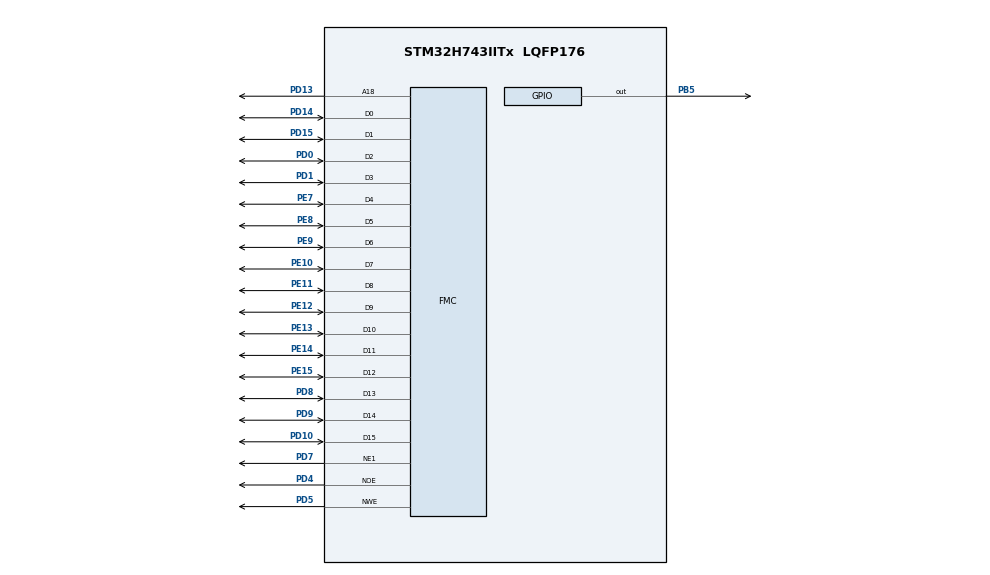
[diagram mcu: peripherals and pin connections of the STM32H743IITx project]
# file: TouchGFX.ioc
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CORTEX_M7.AccessPermission_S-Cortex_Memory_Protection_Unit_Region1_Settings_S=MPU_REGION_FULL_ACCESS
CORTEX_M7.BaseAddress_S-Cortex_Memory_Protection_Unit_Region1_Settings_S=0x60000000
CORTEX_M7.DisableExec_S-Cortex_Memory_Protection_Unit_Region1_Settings_S=MPU_INSTRUCTION_ACCESS_DISABLE
CORTEX_M7.Enable_S-Cortex_Memory_Protection_Unit_Region1_Settings_S=MPU_REGION_ENABLE
CORTEX_M7.Enable_Spec=__NULL
CORTEX_M7.Size_S-Cortex_Memory_Protection_Unit_Region1_Settings_S=MPU_REGION_SIZE_256MB
CORTEX_M7.default_mode_Activation=1
FMC.AddressSetupTime1=3
FMC.BusTurnAroundDuration1=0
FMC.DataSetupTime1=36
FMC.ExtendedAddressSetupTime1=0
FMC.ExtendedBusTurnAroundDuration1=0
FMC.ExtendedDataSetupTime1=4
FMC.ExtendedMode1=FMC_EXTENDED_MODE_ENABLE
Mcu.Family=STM32H7
Mcu.Name=STM32H743IITx
Mcu.Package=LQFP176
NVIC.PriorityGroup=NVIC_PRIORITYGROUP_4
PA13\ (JTMS/SWDIO).Mode=Serial_Wire
PA13\ (JTMS/SWDIO).Signal=DEBUG_JTMS-SWDIO
PA14\ (JTCK/SWCLK).Mode=Serial_Wire
PA14\ (JTCK/SWCLK).Signal=DEBUG_JTCK-SWCLK
PB5.GPIO_ModeDefaultOutputPP=GPIO_MODE_OUTPUT_PP
PB5.GPIO_PuPd=GPIO_PULLUP
PB5.PinState=GPIO_PIN_SET
PB5.Signal=GPIO_Output
PC14-OSC32_IN\ (OSC32_IN).Mode=LSE-External-Oscillator
PC14-OSC32_IN\ (OSC32_IN).Signal=RCC_OSC32_IN
PC15-OSC32_OUT\ (OSC32_OUT).Mode=LSE-External-Oscillator
PC15-OSC32_OUT\ (OSC32_OUT).Signal=RCC_OSC32_OUT
PD0.Signal=FMC_D2_DA2
PD1.Signal=FMC_D3_DA3
PD10.Signal=FMC_D15_DA15
PD13.Signal=FMC_A18
PD14.Signal=FMC_D0_DA0
PD15.Signal=FMC_D1_DA1
PD4.Signal=FMC_NOE
PD5.Signal=FMC_NWE
PD7.Mode=NorPsramChipSelect1_1
PD7.Signal=FMC_NE1
PD8.Signal=FMC_D13_DA13
PD9.Signal=FMC_D14_DA14
PE10.Signal=FMC_D7_DA7
PE11.Signal=FMC_D8_DA8
PE12.Signal=FMC_D9_DA9
PE13.Signal=FMC_D10_DA10
PE14.Signal=FMC_D11_DA11
PE15.Signal=FMC_D12_DA12
PE7.Signal=FMC_D4_DA4
PE8.Signal=FMC_D5_DA5
PE9.Signal=FMC_D6_DA6
PH0-OSC_IN\ (PH0).Mode=HSE-External-Oscillator
PH0-OSC_IN\ (PH0).Signal=RCC_OSC_IN
PH1-OSC_OUT\ (PH1).Mode=HSE-External-Oscillator
PH1-OSC_OUT\ (PH1).Signal=RCC_OSC_OUT
ProjectManager.HeapSize=0x200
ProjectManager.StackSize=0x400
ProjectManager.TargetToolchain=STM32CubeIDE
RCC.ADCFreq_Value=50390625
RCC.APB1Freq_Value=120000000
RCC.APB2Freq_Value=120000000
RCC.APB3Freq_Value=120000000
RCC.APB4Freq_Value=120000000
RCC.CortexFreq_Value=480000000
RCC.D1PPRE=RCC_APB3_DIV2
RCC.D2PPRE1=RCC_APB1_DIV2
RCC.D2PPRE2=RCC_APB2_DIV2
RCC.D3PPRE=RCC_APB4_DIV2
RCC.DIVM1=5
RCC.DIVN1=192
RCC.HCLKFreq_Value=240000000
RCC.HPRE=RCC_HCLK_DIV2
RCC.PLLSourceVirtual=RCC_PLLSOURCE_HSE
RCC.SYSCLKFreq_VALUE=480000000
RCC.SYSCLKSource=RCC_SYSCLKSOURCE_PLLCLK
RCC.USBFreq_Value=480000000
SH.FMC_A18.0=FMC_A18,A18_1
SH.FMC_D0_DA0.0=FMC_D0,16b-d1
SH.FMC_D10_DA10.0=FMC_D10,16b-d1
SH.FMC_D11_DA11.0=FMC_D11,16b-d1
SH.FMC_D12_DA12.0=FMC_D12,16b-d1
SH.FMC_D13_DA13.0=FMC_D13,16b-d1
SH.FMC_D14_DA14.0=FMC_D14,16b-d1
SH.FMC_D15_DA15.0=FMC_D15,16b-d1
SH.FMC_D1_DA1.0=FMC_D1,16b-d1
SH.FMC_D2_DA2.0=FMC_D2,16b-d1
SH.FMC_D3_DA3.0=FMC_D3,16b-d1
SH.FMC_D4_DA4.0=FMC_D4,16b-d1
SH.FMC_D5_DA5.0=FMC_D5,16b-d1
SH.FMC_D6_DA6.0=FMC_D6,16b-d1
SH.FMC_D7_DA7.0=FMC_D7,16b-d1
SH.FMC_D8_DA8.0=FMC_D8,16b-d1
SH.FMC_D9_DA9.0=FMC_D9,16b-d1
SH.FMC_NOE.0=FMC_NOE,Lcd1
SH.FMC_NWE.0=FMC_NWE,Lcd1
STMicroelectronics.X-CUBE-TOUCHGFX.4.24.2.ApplicationCcGraphicsJjApplication=TouchGFXOoGenerator
STMicroelectronics.X-CUBE-TOUCHGFX.4.24.2.tgfx_buffering_strategy=Partial
STMicroelectronics.X-CUBE-TOUCHGFX.4.24.2.tgfx_custom_height=800
STMicroelectronics.X-CUBE-TOUCHGFX.4.24.2.tgfx_custom_width=480
STMicroelectronics.X-CUBE-TOUCHGFX.4.24.2_IsPackSelfContextualization=true
VP_CRC_VS_CRC.Mode=CRC_Activate
VP_MEMORYMAP_VS_MEMORYMAP.Mode=CurAppReg
VP_STMicroelectronics.X-CUBE-TOUCHGFX_VS_GraphicsJjApplication_4.24.2.Mode=GraphicsJjApplication
board=custom

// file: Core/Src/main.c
/* USER CODE BEGIN Header */
/**
  ******************************************************************************
  * @file           : main.c
  * @brief          : Main program body
  ******************************************************************************
  * @attention
  *
  * Copyright (c) 2025 STMicroelectronics.
  * All rights reserved.
  *
  * This software is licensed under terms that can be found in the LICENSE file
  * in the root directory of this software component.
  * If no LICENSE file comes with this software, it is provided AS-IS.
  *
  ******************************************************************************
  */
/* USER CODE END Header */
#include "main.h"
#include "crc.h"
#include "memorymap.h"
#include "gpio.h"
#include "fmc.h"
#include "app_touchgfx.h"

/* USER CODE BEGIN Includes */
extern void touchgfxSignalVSync(void);
#include "./NT35510/NT35510.h"
/* USER CODE END Includes */

void SystemClock_Config(void);
static void MPU_Config(void);

int main(void)
{

  /* MPU Configuration--------------------------------------------------------*/
  MPU_Config();

  /* MCU Configuration--------------------------------------------------------*/

  /* Reset of all peripherals, Initializes the Flash interface and the Systick. */
  HAL_Init();

  /* Configure the system clock */
  SystemClock_Config();

  /* Initialize all configured peripherals */
  MX_GPIO_Init();
  MX_FMC_Init();
  MX_CRC_Init();
  MX_TouchGFX_Init();
  /* USER CODE BEGIN 2 */
  nt35510_init();
  /* USER CODE END 2 */

  /* Infinite loop */
  while (1)
  {

  MX_TouchGFX_Process();
  touchgfxSignalVSync();
  }
}

void SystemClock_Config(void)
{
  RCC_OscInitTypeDef RCC_OscInitStruct = {0};
  RCC_ClkInitTypeDef RCC_ClkInitStruct = {0};

  /** Supply configuration update enable
  */
  HAL_PWREx_ConfigSupply(PWR_LDO_SUPPLY);

  /** Configure the main internal regulator output voltage
  */
  __HAL_PWR_VOLTAGESCALING_CONFIG(PWR_REGULATOR_VOLTAGE_SCALE1);

  while(!__HAL_PWR_GET_FLAG(PWR_FLAG_VOSRDY)) {}

  __HAL_RCC_SYSCFG_CLK_ENABLE();
  __HAL_PWR_VOLTAGESCALING_CONFIG(PWR_REGULATOR_VOLTAGE_SCALE0);

  while(!__HAL_PWR_GET_FLAG(PWR_FLAG_VOSRDY)) {}

  /** Initializes the RCC Oscillators according to the specified parameters
  * in the RCC_OscInitTypeDef structure.
  */
  RCC_OscInitStruct.OscillatorType = RCC_OSCILLATORTYPE_HSE;
  RCC_OscInitStruct.HSEState = RCC_HSE_ON;
  RCC_OscInitStruct.PLL.PLLState = RCC_PLL_ON;
  RCC_OscInitStruct.PLL.PLLSource = RCC_PLLSOURCE_HSE;
  RCC_OscInitStruct.PLL.PLLM = 5;
  RCC_OscInitStruct.PLL.PLLN = 192;
  RCC_OscInitStruct.PLL.PLLP = 2;
  RCC_OscInitStruct.PLL.PLLQ = 2;
  RCC_OscInitStruct.PLL.PLLR = 2;
  RCC_OscInitStruct.PLL.PLLRGE = RCC_PLL1VCIRANGE_2;
  RCC_OscInitStruct.PLL.PLLVCOSEL = RCC_PLL1VCOWIDE;
  RCC_OscInitStruct.PLL.PLLFRACN = 0;
  if (HAL_RCC_OscConfig(&RCC_OscInitStruct) != HAL_OK)
  {
    Error_Handler();
  }

  /** Initializes the CPU, AHB and APB buses clocks
  */
  RCC_ClkInitStruct.ClockType = RCC_CLOCKTYPE_HCLK|RCC_CLOCKTYPE_SYSCLK
                              |RCC_CLOCKTYPE_PCLK1|RCC_CLOCKTYPE_PCLK2
                              |RCC_CLOCKTYPE_D3PCLK1|RCC_CLOCKTYPE_D1PCLK1;
  RCC_ClkInitStruct.SYSCLKSource = RCC_SYSCLKSOURCE_PLLCLK;
  RCC_ClkInitStruct.SYSCLKDivider = RCC_SYSCLK_DIV1;
  RCC_ClkInitStruct.AHBCLKDivider = RCC_HCLK_DIV2;
  RCC_ClkInitStruct.APB3CLKDivider = RCC_APB3_DIV2;
  RCC_ClkInitStruct.APB1CLKDivider = RCC_APB1_DIV2;
  RCC_ClkInitStruct.APB2CLKDivider = RCC_APB2_DIV2;
  RCC_ClkInitStruct.APB4CLKDivider = RCC_APB4_DIV2;

  if (HAL_RCC_ClockConfig(&RCC_ClkInitStruct, FLASH_LATENCY_4) != HAL_OK)
  {
    Error_Handler();
  }
}

 /* MPU Configuration */

void MPU_Config(void)
{
  MPU_Region_InitTypeDef MPU_InitStruct = {0};

  /* Disables the MPU */
  HAL_MPU_Disable();

  /** Initializes and configures the Region and the memory to be protected
  */
  MPU_InitStruct.Enable = MPU_REGION_ENABLE;
  MPU_InitStruct.BaseAddress = 0x60000000;
  MPU_InitStruct.Size = MPU_REGION_SIZE_256MB;
  MPU_InitStruct.SubRegionDisable = 0x0;
  MPU_InitStruct.TypeExtField = MPU_TEX_LEVEL0;
  MPU_InitStruct.AccessPermission = MPU_REGION_FULL_ACCESS;
  MPU_InitStruct.DisableExec = MPU_INSTRUCTION_ACCESS_DISABLE;
  MPU_InitStruct.IsShareable = MPU_ACCESS_NOT_SHAREABLE;
  MPU_InitStruct.IsCacheable = MPU_ACCESS_NOT_CACHEABLE;
  MPU_InitStruct.IsBufferable = MPU_ACCESS_NOT_BUFFERABLE;

  HAL_MPU_ConfigRegion(&MPU_InitStruct);
  /* Enables the MPU */
  HAL_MPU_Enable(MPU_PRIVILEGED_DEFAULT);

}

void Error_Handler(void)
{
  __disable_irq();
  while (1)
  {
  }
}
